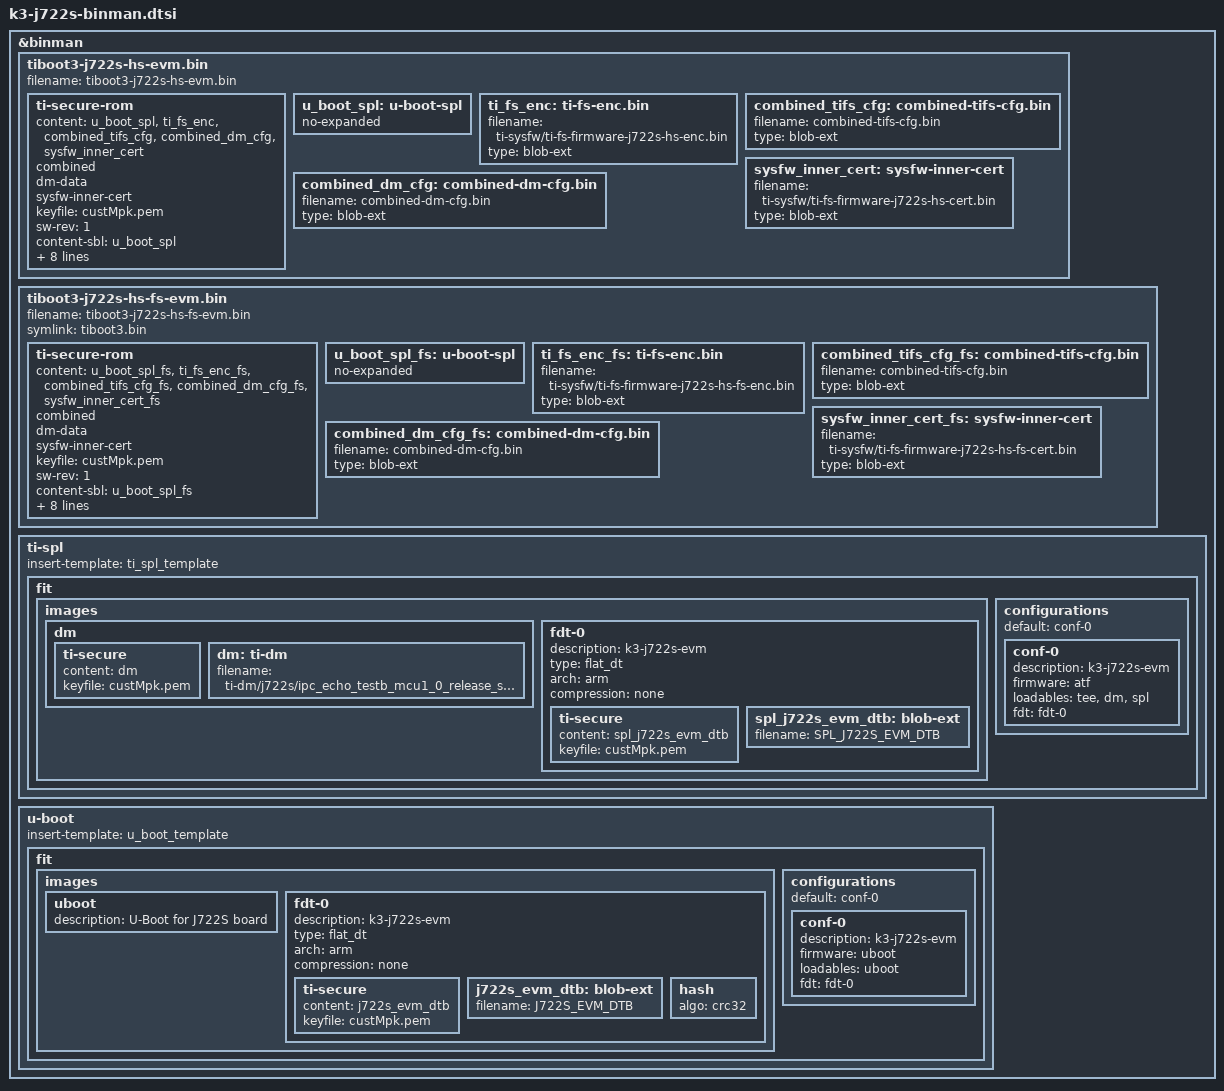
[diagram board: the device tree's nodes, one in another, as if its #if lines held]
// SPDX-License-Identifier: GPL-2.0
/*
 * Copyright (C) 2024 Texas Instruments Incorporated - https://www.ti.com/
 */

#include "k3-binman.dtsi"

#if IS_ENABLED(CONFIG_TARGET_J722S_R5_EVM)

&binman {
	tiboot3-j722s-hs-evm.bin {
		filename = "tiboot3-j722s-hs-evm.bin";
		ti-secure-rom {
			content = <&u_boot_spl>, <&ti_fs_enc>, <&combined_tifs_cfg>,
				  <&combined_dm_cfg>, <&sysfw_inner_cert>;
			combined;
			dm-data;
			sysfw-inner-cert;
			keyfile = "custMpk.pem";
			sw-rev = <1>;
			content-sbl = <&u_boot_spl>;
			content-sysfw = <&ti_fs_enc>;
			content-sysfw-data = <&combined_tifs_cfg>;
			content-sysfw-inner-cert = <&sysfw_inner_cert>;
			content-dm-data = <&combined_dm_cfg>;
			load = <CONFIG_SPL_TEXT_BASE>;
			load-sysfw = <0x40000>;
			load-sysfw-data = <0x67000>;
			load-dm-data = <0x43c7a800>;
		};

		u_boot_spl: u-boot-spl {
			no-expanded;
		};

		ti_fs_enc: ti-fs-enc.bin {
			filename = "ti-sysfw/ti-fs-firmware-j722s-hs-enc.bin";
			type = "blob-ext";
		};

		combined_tifs_cfg: combined-tifs-cfg.bin {
			filename = "combined-tifs-cfg.bin";
			type = "blob-ext";
		};

		sysfw_inner_cert: sysfw-inner-cert {
			filename = "ti-sysfw/ti-fs-firmware-j722s-hs-cert.bin";
			type = "blob-ext";
		};

		combined_dm_cfg: combined-dm-cfg.bin {
			filename = "combined-dm-cfg.bin";
			type = "blob-ext";
		};
	};
};

&binman {
	tiboot3-j722s-hs-fs-evm.bin {
		filename = "tiboot3-j722s-hs-fs-evm.bin";
		symlink = "tiboot3.bin";

		ti-secure-rom {
			content = <&u_boot_spl_fs>, <&ti_fs_enc_fs>, <&combined_tifs_cfg_fs>,
				  <&combined_dm_cfg_fs>, <&sysfw_inner_cert_fs>;
			combined;
			dm-data;
			sysfw-inner-cert;
			keyfile = "custMpk.pem";
			sw-rev = <1>;
			content-sbl = <&u_boot_spl_fs>;
			content-sysfw = <&ti_fs_enc_fs>;
			content-sysfw-data = <&combined_tifs_cfg_fs>;
			content-sysfw-inner-cert = <&sysfw_inner_cert_fs>;
			content-dm-data = <&combined_dm_cfg_fs>;
			load = <CONFIG_SPL_TEXT_BASE>;
			load-sysfw = <0x40000>;
			load-sysfw-data = <0x67000>;
			load-dm-data = <0x43c7a800>;
		};

		u_boot_spl_fs: u-boot-spl {
			no-expanded;
		};

		ti_fs_enc_fs: ti-fs-enc.bin {
			filename = "ti-sysfw/ti-fs-firmware-j722s-hs-fs-enc.bin";
			type = "blob-ext";
		};

		combined_tifs_cfg_fs: combined-tifs-cfg.bin {
			filename = "combined-tifs-cfg.bin";
			type = "blob-ext";
		};

		sysfw_inner_cert_fs: sysfw-inner-cert {
			filename = "ti-sysfw/ti-fs-firmware-j722s-hs-fs-cert.bin";
			type = "blob-ext";
		};

		combined_dm_cfg_fs: combined-dm-cfg.bin {
			filename = "combined-dm-cfg.bin";
			type = "blob-ext";
		};
	};
};
#endif /*CONFIG_TARGET_J722S_R5_EVM*/

#if IS_ENABLED(CONFIG_TARGET_J722S_A53_EVM)

#define SPL_J722S_EVM_DTB "spl/dts/ti/k3-j722s-evm.dtb"
#define J722S_EVM_DTB "u-boot.dtb"

&binman {
	ti-spl {
		insert-template = <&ti_spl_template>;

		fit {
			images {
				dm {
					ti-secure {
						content = <&dm>;
						keyfile = "custMpk.pem";
					};

					dm: ti-dm {
						filename = "ti-dm/j722s/ipc_echo_testb_mcu1_0_release_strip.xer5f";
					};
				};

				fdt-0 {
					description = "k3-j722s-evm";
					type = "flat_dt";
					arch = "arm";
					compression = "none";

					ti-secure {
						content = <&spl_j722s_evm_dtb>;
						keyfile = "custMpk.pem";
					};

					spl_j722s_evm_dtb: blob-ext {
						filename = SPL_J722S_EVM_DTB;
					};

				};

			};

			configurations {
				default = "conf-0";

				conf-0 {
					description = "k3-j722s-evm";
					firmware = "atf";
					loadables = "tee", "dm", "spl";
					fdt = "fdt-0";
				};
			};
		};
	};
};

&binman {
	u-boot {
		insert-template = <&u_boot_template>;

		fit {
			images {
				uboot {
					description = "U-Boot for J722S board";
				};

				fdt-0 {
					description = "k3-j722s-evm";
					type = "flat_dt";
					arch = "arm";
					compression = "none";

					ti-secure {
						content = <&j722s_evm_dtb>;
						keyfile = "custMpk.pem";
					};

					j722s_evm_dtb: blob-ext {
						filename = J722S_EVM_DTB;
					};

					hash {
						algo = "crc32";
					};
				};
			};

			configurations {
				default = "conf-0";

				conf-0 {
					description = "k3-j722s-evm";
					firmware = "uboot";
					loadables = "uboot";
					fdt = "fdt-0";
				};

			};
		};
	};
};
#endif /*CONFIG_TARGET_J722S_A53_EVM*/
